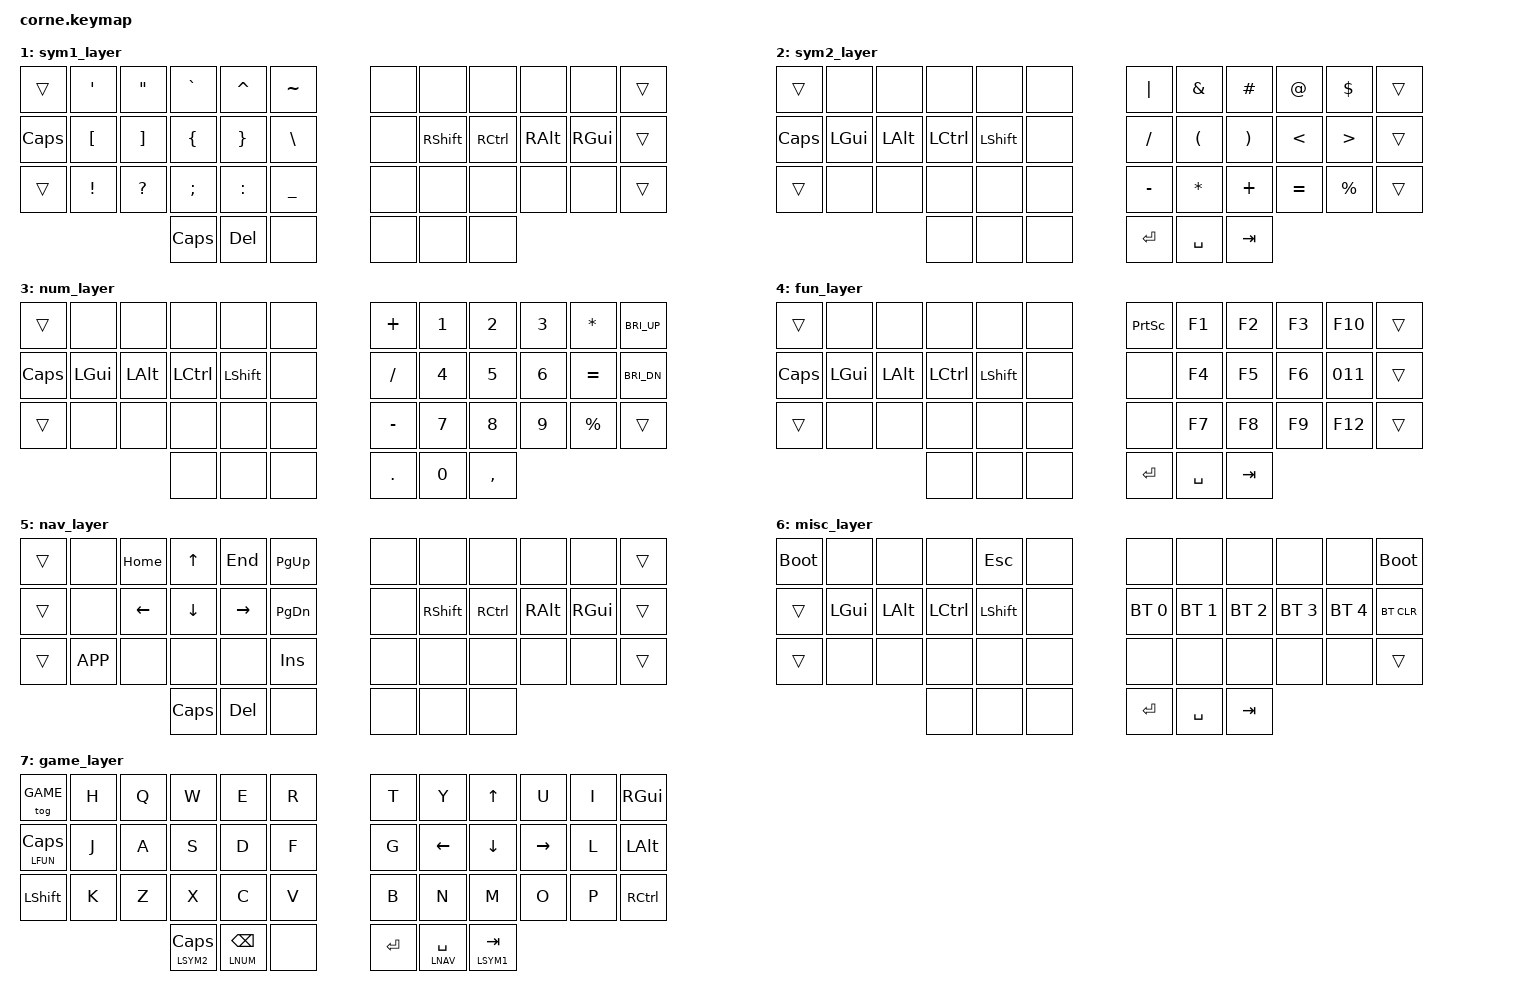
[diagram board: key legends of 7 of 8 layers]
/*
 * Copyright (c) 2020 The ZMK Contributors
 *
 * SPDX-License-Identifier: MIT
 */

#include <behaviors.dtsi>
#include <dt-bindings/zmk/keys.h>
#include <dt-bindings/zmk/bt.h>

#define ML(k1,k2,k3,k4) &lh_pht  LGUI   k1  &lh_pht LALT  k2  &lh_pht LCTRL k3  &lhs_pht LSHIFT k4
#define MR(k1,k2,k3,k4) &rhs_pht RSHIFT k1  &rh_pht RCTRL k2  &rh_pht RALT  k3  &rh_pht  RGUI   k4
#define LSYM1  1
#define LSYM2  2
#define LNUM   3
#define LFUN   4
#define LNAV   5
#define LMISC  6
#define GAME   7

/ {
behaviors {
  lhs_pht: left_hand_shift_positional_hold_tap {
    compatible = "zmk,behavior-hold-tap";
    label = "LEFT_SHIFT_POSITIONAL_HOLD_TAP";
    #binding-cells = <2>;
    flavor = "balanced";
    tapping-term-ms = <150>;
    quick-tap-ms = <0>;
    bindings = <&kp>, <&kp>;
    hold-trigger-key-positions =         // <---[[right-hand keys]]
    <              6  7  8  9  10 11
     13 14 15 16   18 19 20 21 22 23
                   30 31 32 33 34 35
                   39 40 41>; 
  };

  rhs_pht: right_hand_shift_positional_hold_tap {
    compatible = "zmk,behavior-hold-tap";
    label = "RIGHT_SHIFT_POSITIONAL_HOLD_TAP";
    #binding-cells = <2>;
    flavor = "balanced";
    tapping-term-ms = <150>;
    quick-tap-ms = <0>;
    bindings = <&kp>, <&kp>;
    hold-trigger-key-positions =         // <---[[left-hand keys]]
    <0  1  2  3  4  5
     12 13 14 15 16 17  19 20 21 22
     24 25 26 27 28 29  
     36 37 38>;         
  };                    
  lh_pht: left_hand_positional_hold_tap {
    compatible = "zmk,behavior-hold-tap";
    label = "LEFT_POSITIONAL_HOLD_TAP";
    #binding-cells = <2>;
    flavor = "tap-preferred";
    tapping-term-ms = <250>;
    quick-tap-ms = <0>;
    bindings = <&kp>, <&kp>;
    hold-trigger-key-positions =         // <---[[right-hand keys]]
    <              6  7  8  9  10 11
     13 14 15 16   18 19 20 21 22 23
                   30 31 32 33 34 35
                   39 40 41>; 
  };

  rh_pht: right_hand_positional_hold_tap {
    compatible = "zmk,behavior-hold-tap";
    label = "RIGHT_POSITIONAL_HOLD_TAP";
    #binding-cells = <2>;
    flavor = "tap-preferred";
    tapping-term-ms = <250>;
    quick-tap-ms = <0>;
    bindings = <&kp>, <&kp>;
    hold-trigger-key-positions =         // <---[[left-hand keys]]
    <0  1  2  3  4  5
     12 13 14 15 16 17  19 20 21 22
     24 25 26 27 28 29  
     36 37 38>;         
  };                    
};

keymap {
  compatible = "zmk,keymap";

// ----------------------------------------------------------------------------------------
// game layer       '      ,      .       p         y         f    g        c       r      l      vol_up  
// esc(fun)         a(win) o(alt) e(ctrl) u(shift)  i         d    h(shift) t(ctrl) n(alt) s(win) vol_dn
// play/pause(misc) 102    q      j       k         x         b    m        w       v      z      mute
//                            esc(sym2) bksp(num)  --         enter    space(nav)   tab(sym1)
// ----------------------------------------------------------------------------------------
  default_layer {
  bindings = <
  &tog GAME         &kp SQT  &kp COMMA &kp DOT &kp P &kp Y   &kp F    &kp G &kp C &kp R   &kp L &kp C_VOL_UP
  &lt  LFUN CAPS ML(A,       O,        E,      U)    &kp I   &kp D MR(H,    T,    N,      S)    &kp C_VOL_DN 
  &lt  LMISC C_PP   &kp RALT &kp Q     &kp J   &kp K &kp X   &kp B    &kp M &kp W &kp V   &kp Z &kp C_MUTE
                    &lt LSYM2 CAPS  &lt LNUM BSPC    &none   &kp RET  &lt LNAV SPACE   &lt LSYM1 TAB
  >;
  };

// ----------------------------------------------------------------------------------------
// --   '    "    `    ^    ~         XX   XX    XX    XX    XX   --
// esc  [    ]    {    }    \         XX   shift ctrl  alt   win  --
// --   !    ?    ;    :    _         XX   XX    XX    XX    XX   --
//            esc    del   --         XX   XX    XX
// ----------------------------------------------------------------------------------------
  sym1_layer {
  bindings = <
  &trans    &kp SQT   &kp DQT   &kp GRAVE  &kp CARET  &kp TILDE      &none  &none      &none     &none     &none    &trans
  &kp CAPS  &kp LBKT  &kp RBKT  &kp LBRC   &kp RBRC   &kp BSLH       &none  &kp RSHIFT &kp RCTRL &kp RALT  &kp RGUI &trans
  &trans    &kp EXCL  &kp QMARK &kp SEMI   &kp COLON  &kp UNDER      &none  &none      &none     &none     &none    &trans
                                &kp CAPS   &kp DEL        &none      &none  &none      &none
  >;
  };

// ----------------------------------------------------------------------------------------
// --   XX    XX    XX    XX    XX        |    &    #    @    $   --
// esc  win   alt   ctrl  shift XX        /    (    )    <    >   --
// --   XX    XX    XX    XX    XX        -    *    +    =    %   --
//                  XX    XX    XX        enter  space  tab
// ----------------------------------------------------------------------------------------
  sym2_layer {
  bindings = <
  &trans   &none    &none    &none     &none      &none    &kp PIPE  &kp AMPS  &kp HASH  &kp AT    &kp DLLR  &trans
  &kp CAPS &kp LGUI &kp LALT &kp LCTRL &kp LSHIFT &none    &kp FSLH  &kp LPAR  &kp RPAR  &kp LT    &kp GT    &trans
  &trans   &none    &none    &none     &none      &none    &kp MINUS &kp STAR  &kp PLUS  &kp EQUAL &kp PRCNT &trans
                                      &none &none &none    &kp RET   &kp SPACE  &kp TAB
  >;
  };

// ----------------------------------------------------------------------------------------
// --   XX     XX     XX      XX       XX         +     1     2    3    *   bri_up
// esc  win    alt    ctrl    shift    XX         /     4     5    6    =   bri_dn
// --   XX     XX     XX      XX       XX         -     7     8    9    %   --
//                    XX      XX       XX         .     0     ,
// ----------------------------------------------------------------------------------------
  num_layer {
  bindings = <
  &trans    &none    &none     &none     &none      &none    &kp PLUS   &kp N1  &kp N2  &kp N3  &kp STAR  &kp C_BRI_UP
  &kp CAPS  &kp LGUI &kp LALT  &kp LCTRL &kp LSHIFT &none    &kp FSLH   &kp N4  &kp N5  &kp N6  &kp EQUAL &kp C_BRI_DN
  &trans    &none    &none     &none     &none      &none    &kp MINUS  &kp N7  &kp N8  &kp N9  &kp PRCNT &trans
                                     &none  &none   &none    &kp DOT &kp N0  &kp COMMA
  >;
  };

// ----------------------------------------------------------------------------------------
// --   XX     XX     XX      XX       XX      prtsc f1    f2   f3    f10   --
// esc  win    alt    ctrl    shift    XX      XX    f4    f5   f6    f11   --
// --   XX     XX     XX      XX       XX      XX    f7    f8   f9    f12   --
//                    XX      XX       XX      enter space  tab
// ----------------------------------------------------------------------------------------
  fun_layer {
  bindings = <
  &trans    &none    &none     &none     &none      &none    &kp PSCRN &kp F1  &kp F2  &kp F3  &kp F10  &trans
  &kp CAPS  &kp LGUI &kp LALT  &kp LCTRL &kp LSHIFT &none    &none     &kp F4  &kp F5  &kp F6  &kp 011  &trans
  &trans    &none    &none     &none     &none      &none    &none     &kp F7  &kp F8  &kp F9  &kp F12  &trans
                                        &none &none &none    &kp RET   &kp SPACE  &kp TAB
  >;
  };

// ----------------------------------------------------------------------------------------
// --   caps   home  ^   end  pup         XX   XX    XX    XX    XX   -- 
// --   XX     <-    v   ->   pdown       XX   shift ctrl  alt   win  -- 
// --   app    XX    XX  XX   ins         XX   XX    XX    XX    XX   --
//                   esc del  --          XX   XX    XX
// ----------------------------------------------------------------------------------------
  nav_layer {
  bindings = <
  &trans  &none     &kp HOME &kp UP   &kp END   &kp PG_UP      &none  &none      &none     &none     &none    &trans
  &trans  &none     &kp LEFT &kp DOWN &kp RIGHT &kp PG_DN      &none  &kp RSHIFT &kp RCTRL &kp RALT  &kp RGUI &trans
  &trans  &kp K_APP &none    &none    &none     &kp INS        &none  &none      &none     &none     &none    &trans
                             &kp CAPS &kp DEL       &none      &none  &none      &none
  >;
  };

// ----------------------------------------------------------------------------------------
// boot XX    XX    XX    XX    XX        caps   XX    XX    XX   XX   boot
// --   win   alt   ctrl  shift XX        bt0  bt1   bt2   bt3  bt4  bclr
// --   XX    XX    XX    XX    XX        XX   XX    XX    XX   XX   --
//                  XX    XX    XX        enter space  tab
// ----------------------------------------------------------------------------------------
  misc_layer {
  bindings = <
  &bootloader  &none      &none     &none      &kp ESC   &none     &none         &none         &none         &none      &none         &bootloader
  &trans &kp LGUI &kp LALT &kp LCTRL &kp LSHIFT &none     &bt BT_SEL 0  &bt BT_SEL 1  &bt BT_SEL 2  &bt BT_SEL 3  &bt BT_SEL 4  &bt BT_CLR
  &trans &none    &none    &none     &none      &none     &none         &none         &none         &none      &none         &trans
                           &none     &none      &none     &kp RET    &kp SPACE    &kp TAB
  >;
  };

// ----------------------------------------------------------------------------------------
// --    H    Q    W    E    R        T  Y    UP    U     I  WIN
// --    J    A    S    D    F        G  LEFT DOWN  RIGHT H  ALT
// SHIFT K    Z    X    C    V        B  N    M     O     P  CTRL
//               --   --   --        -- --  --
// ----------------------------------------------------------------------------------------
  game_layer {
  bindings = <
  &tog GAME       &kp H  &kp Q  &kp W  &kp E  &kp R     &kp T   &kp Y    &kp UP    &kp U     &kp I  &kp RGUI
  &lt  LFUN CAPS  &kp J  &kp A  &kp S  &kp D  &kp F     &kp G   &kp LEFT &kp DOWN  &kp RIGHT &kp L  &kp LALT
  &kp LSHIFT      &kp K  &kp Z  &kp X  &kp C  &kp V     &kp B   &kp N    &kp M     &kp O     &kp P  &kp RCTRL
             &lt LSYM2 CAPS  &lt LNUM BSPC    &none     &kp RET  &lt LNAV SPACE   &lt LSYM1 TAB
  >;
  };

};
};
